# STM32L562 register map
File version: 1.1
Registers are 32-bit, read-write, reset 0x0 unless marked. A register's access mark holds for its fields unless they carry their own. Offsets are from the block's base; lines under a group give offsets from that group; [hi:lo] are bit positions; {n}, {i} and the like mark numbered series; 'fields as' and 'values as' point back to an identical list; <NAME> marks a mode.

## Memory map
0x40020000 DMA1 size 0x400 — Direct memory access controller

## Interrupts
29 DMA1_Channel1 (DMA1) — DMA1 Channel1 global interrupt
30 DMA1_Channel2 (DMA1) — DMA1 Channel2 global interrupt
31 DMA1_Channel3 (DMA1) — DMA1 Channel3 interrupt
32 DMA1_Channel4 (DMA1) — DMA1 Channel4 interrupt
33 DMA1_Channel5 (DMA1) — DMA1 Channel5 interrupt
34 DMA1_Channel6 (DMA1) — DMA1 Channel6 interrupt
35 DMA1_Channel7 (DMA1) — DMA1 Channel 7 interrupt
36 DMA1_Channel8 (DMA1)

## DMA1 — Direct memory access controller
Base 0x40020000
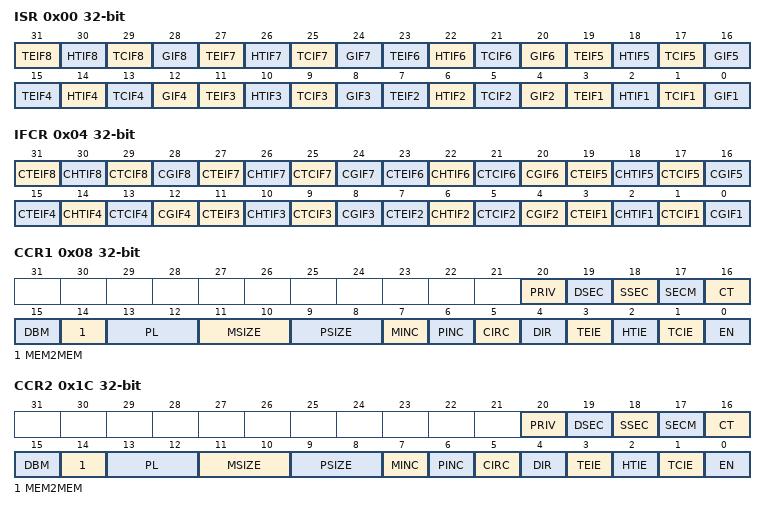
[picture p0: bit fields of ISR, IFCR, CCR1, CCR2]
0x00 ISR ro — interrupt status register
  [31] TEIF8 — transfer error (TE) flag for channel 8
  [30] HTIF8 — half transfer (HT) flag for channel 8
  [29] TCIF8 — transfer complete (TC) flag for channel 8
  [28] GIF8 — global interrupt flag for channel 8
  [4n-1] TEIF{n} (n=1..7) — Channel x transfer error flag (x = 1 ..7)
  [4n-2] HTIF{n} (n=1..7) — Channel x half transfer flag (x = 1 ..7)
  [4n-3] TCIF{n} (n=1..7) — Channel x transfer complete flag (x = 1 ..7)
  [4n-4] GIF{n} (n=1..7) — Channel x global interrupt flag (x = 1 ..7)
0x04 IFCR wo — interrupt flag clear register
  [31] CTEIF8 — transfer error flag clear for channel 8
  [30] CHTIF8 — half transfer flag clear for channel 8
  [29] CTCIF8 — transfer complete flag clear for channel 8
  [28] CGIF8 — global interrupt flag clear for channel 8
  [4n-1] CTEIF{n} (n=1..7) — Channel x transfer error clear (x = 1 ..7)
  [4n-2] CHTIF{n} (n=1..7) — Channel x half transfer clear (x = 1 ..7)
  [4n-3] CTCIF{n} (n=1..7) — Channel x transfer complete clear (x = 1 ..7)
  [4n-4] CGIF{n} (n=1..7) — Channel x global interrupt clear (x = 1 ..7)
0x08 CCR1 — channel x configuration register
  [20] PRIV — privileged mode
  [19] DSEC — security of the DMA transfer to the destination
  [18] SSEC — security of the DMA transfer from the source
  [17] SECM — secure mode
  [16] CT — current target memory of DMA transfer in double-buffer mode
  [15] DBM — double-buffer mode
  [14] MEM2MEM — Memory to memory mode
  [13:12] PL — Channel priority level
  [11:10] MSIZE — Memory size
  [9:8] PSIZE — Peripheral size
  [7] MINC — Memory increment mode
  [6] PINC — Peripheral increment mode
  [5] CIRC — Circular mode
  [4] DIR — Data transfer direction
  [3] TEIE — Transfer error interrupt enable
  [2] HTIE — Half transfer interrupt enable
  [1] TCIE — Transfer complete interrupt enable
  [0] EN — Channel enable
0x0C CNDTR1 — channel x number of data register
  [17:0] NDT — Number of data to transfer
0x10 CPAR1 — channel x peripheral address register
  [31:0] PA — Peripheral address
{0x0+0x14*i} CM0AR{i} (i=1..7) — channel x memory address register
  [31:0] MA — Memory address
{0x4+0x14*i} CM1AR{i} (i=1..7) — channel x memory address register
  [31:0] MA — Memory address
0x1C CCR2 — channel x configuration register
  fields as CCR1
0x20 CNDTR2 — channel x number of data register
  [17:0] NDT — Number of data to transfer
0x24 CPAR2 — channel x peripheral address register
  [31:0] PA — Peripheral address
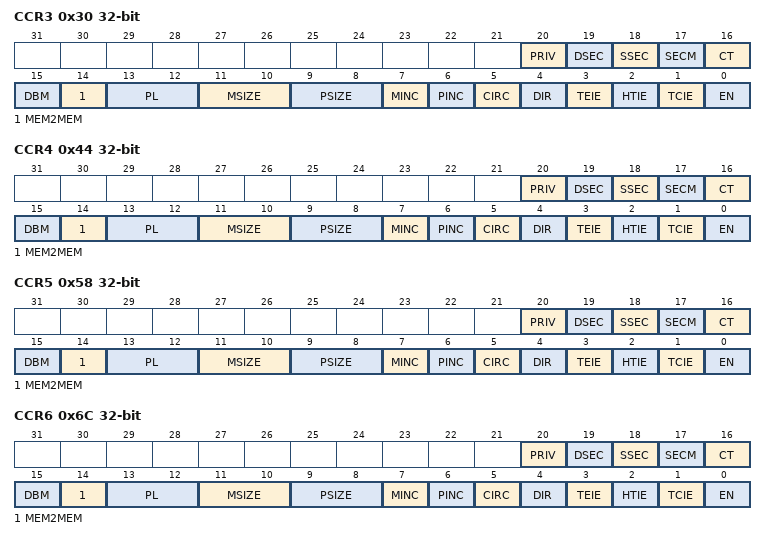
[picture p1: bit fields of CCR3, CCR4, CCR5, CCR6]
0x30 CCR3 — channel x configuration register
  fields as CCR1
0x34 CNDTR3 — channel x number of data register
  [17:0] NDT — Number of data to transfer
0x38 CPAR3 — channel x peripheral address register
  [31:0] PA — Peripheral address
0x44 CCR4 — channel x configuration register
  fields as CCR1
0x48 CNDTR4 — channel x number of data register
  [17:0] NDT — Number of data to transfer
0x4C CPAR4 — channel x peripheral address register
  [31:0] PA — Peripheral address
0x58 CCR5 — channel x configuration register
  fields as CCR1
0x5C CNDTR5 — channel x number of data register
  [17:0] NDT — Number of data to transfer
0x60 CPAR5 — channel x peripheral address register
  [31:0] PA — Peripheral address
0x6C CCR6 — channel x configuration register
  fields as CCR1
0x70 CNDTR6 — channel x number of data register
  [17:0] NDT — Number of data to transfer
0x74 CPAR6 — channel x peripheral address register
  [31:0] PA — Peripheral address
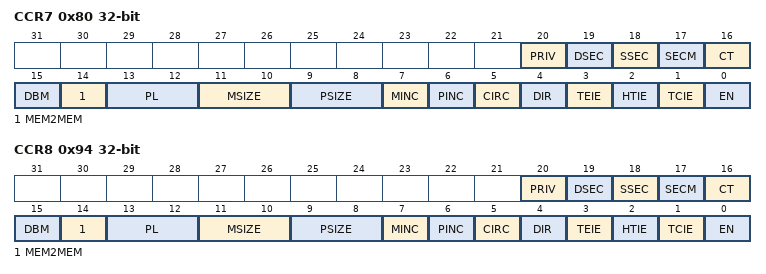
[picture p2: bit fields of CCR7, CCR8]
0x80 CCR7 — channel x configuration register
  fields as CCR1
0x84 CNDTR7 — channel x number of data register
  [17:0] NDT — Number of data to transfer
0x88 CPAR7 — channel x peripheral address register
  [31:0] PA — Peripheral address
0x94 CCR8 — channel x configuration register
  fields as CCR1
0x98 CNDTR8 — channel x number of data register
  [17:0] NDT — Number of data to transfer
0x9C CPAR8 — channel x peripheral address register
  [31:0] PA — Peripheral address
0xA0 CM0AR8 — channel x peripheral address register
  [31:0] MA — Memory address
0xA4 CM1AR8 — channel x peripheral address register
  [31:0] MA — Memory address
0xA8 CSELR — channel selection register
  [31:0] MA — peripheral address
